# nrf54l05_application register map
Vendor: Nordic Semiconductor; Series: nrf54l; File version: 1
CPU: CM33 r0p4, little endian, MPU, FPU, 3 interrupt priority bits, 270 interrupts, 4 SAU regions
Registers are 32-bit, read-write, reset 0x0 unless marked. A register's access mark holds for its fields unless they carry their own. Offsets are from the block's base; [hi:lo] are bit positions; lines under a group give offsets from that group; {n}, {i} and the like mark numbered series.

## GLOBAL_SUPPORT00_S — PCGCSlave 0
Base 0x5005F000
Same registers: GLOBAL_SUPPORT10_S 0x5009E000, GLOBAL_SUPPORT20_S 0x500FF000, GLOBAL_PCGCS30_S 0x5011E000, GLOBAL_SUPPORT30_S 0x5011F000
{0xC00+4i} PENALTY[{i}] (i=0..1) — Description collection: Penalty level for power/clock pair n
  [7:0] PENALTY — Penalty level
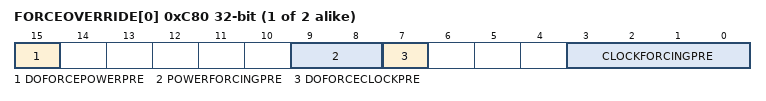
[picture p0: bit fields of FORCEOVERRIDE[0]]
{0xC80+4i} FORCEOVERRIDE[{i}] (i=0..1) — Description collection: Force override of power/clock pair n
  [15] DOFORCEPOWERPRE, [9:8] POWERFORCINGPRE, [7] DOFORCECLOCKPRE, [3:0] CLOCKFORCINGPRE

## GLOBAL_EGU10_NS — Event generator unit 0
Base 0x40087000
Same registers: GLOBAL_EGU20_NS 0x400C9000, GLOBAL_EGU10_S 0x50087000, GLOBAL_EGU20_S 0x500C9000
{0x0+4i} TASKS_TRIGGER[{i}] (i=0..15) wo — Description collection: Trigger n for triggering the corresponding TRIGGERED[n] event
  [0] TASKS_TRIGGER — Trigger n for triggering the corresponding TRIGGERED[n] event
    1=Trigger task
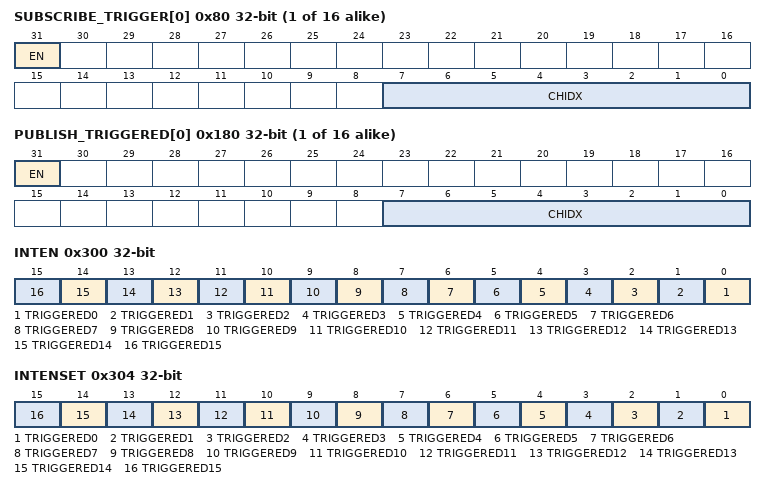
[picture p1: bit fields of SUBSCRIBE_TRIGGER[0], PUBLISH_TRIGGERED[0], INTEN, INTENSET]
{0x80+4i} SUBSCRIBE_TRIGGER[{i}] (i=0..15) — Description collection: Subscribe configuration for task TRIGGER[n]
  [31] EN
    0=Disabled (Disable subscription); 1=Enabled (Enable subscription)
  [7:0] CHIDX — DPPI channel that task TRIGGER[n] will subscribe to
{0x100+4i} EVENTS_TRIGGERED[{i}] (i=0..15) — Description collection: Event number n generated by triggering the corresponding TRIGGER[n] task
  [0] EVENTS_TRIGGERED — Event number n generated by triggering the corresponding TRIGGER[n] task
    0=NotGenerated (Event not generated); 1=Generated (Event generated)
{0x180+4i} PUBLISH_TRIGGERED[{i}] (i=0..15) — Description collection: Publish configuration for event TRIGGERED[n]
  [31] EN
    0=Disabled (Disable publishing); 1=Enabled (Enable publishing)
  [7:0] CHIDX — DPPI channel that event TRIGGERED[n] will publish to
0x300 INTEN — Enable or disable interrupt
  [all] fields
    0=Disabled; 1=Enabled
  [n] TRIGGERED{n} (n=0..15) — Enable or disable interrupt for event TRIGGERED[{n}]
0x304 INTENSET — Enable interrupt
  [all] fields
    on read: 0=Disabled (Read: Disabled); 1=Enabled (Read: Enabled) | on write: 1=Set (Enable)
  [n] TRIGGERED{n} (n=0..15) — Write '1' to enable interrupt for event TRIGGERED[{n}]
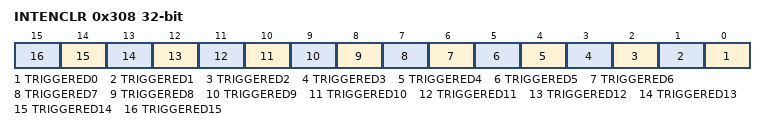
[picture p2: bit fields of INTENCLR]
0x308 INTENCLR — Disable interrupt
  [all] fields
    on read: 0=Disabled (Read: Disabled); 1=Enabled (Read: Enabled) | on write: 1=Clear (Disable)
  [n] TRIGGERED{n} (n=0..15) — Write '1' to disable interrupt for event TRIGGERED[{n}]

## GLOBAL_MEMCONF_NS — Memory configuration 0
Base 0x400CF000
Same registers: GLOBAL_MEMCONF_S 0x500CF000
{0x500+0x10*i} POWER[{i}] (i=0..1) group — Unspecified
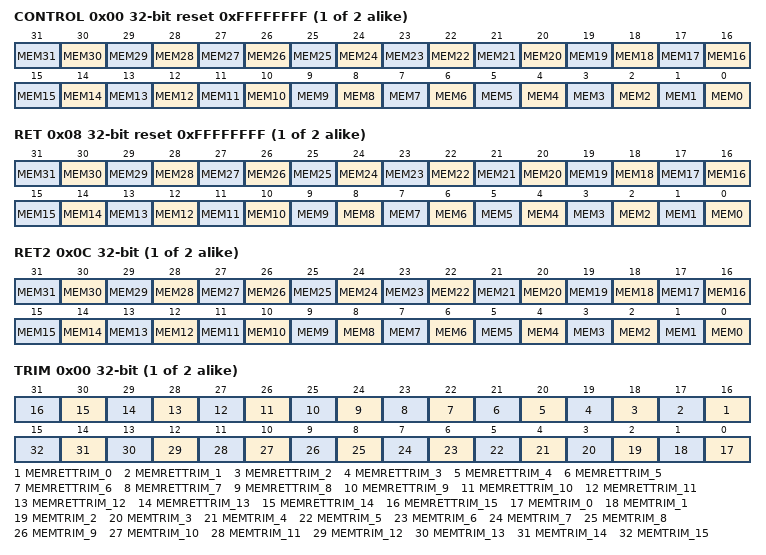
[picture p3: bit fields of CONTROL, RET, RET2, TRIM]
  0x00 CONTROL reset 0xFFFFFFFF — Description cluster: Control memory block power.
    [all] fields
      0=Off (Power down); 1=On (Power up)
    [n] MEM{n} (n=0..31) — Keep the memory block MEM[{n}] on or off when in System ON mode.
  0x08 RET reset 0xFFFFFFFF — Description cluster: RAM retention for RAM [n].
    [all] fields
      0=Off (Retention off); 1=On (Retention on)
    [n] MEM{n} (n=0..31) — Keep the RAM block MEM[{n}] retained when in System OFF mode.
  0x0C RET2 — Description cluster: RAM retention for the second bank in the RAM block
    [all] fields
      0=Off (Retention off); 1=On (Retention on)
    [n] MEM{n} (n=0..31) — Keep the second bank in RAM block MEM[{n}] retained when in System OFF mode.
{0x900+4i} BLOCKTYPE[{i}] (i=0..1) group — Unspecified
  0x00 TRIM — Description cluster: Trim configuration for the memory block types.
    [n+16] MEMRETTRIM_{n} (n=0..15) — Trimming for retention mode for decreased leakage. Must be kept active in RAM retention mode.
    [n] MEMTRIM_{n} (n=0..15) — Read/write margin trim.
